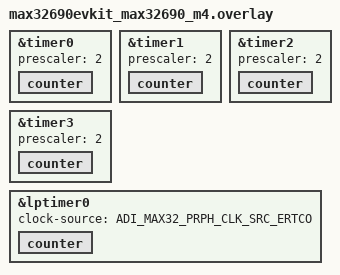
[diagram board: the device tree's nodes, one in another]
/*
 * Copyright (c) 2024 Analog Devices, Inc.
 *
 * SPDX-License-Identifier: Apache-2.0
 */

&timer0 {
	prescaler = <2>;
	status = "okay";

	counter {
		status = "okay";
	};
};

&timer1 {
	prescaler = <2>;
	status = "okay";

	counter {
		status = "okay";
	};
};

&timer2 {
	prescaler = <2>;
	status = "okay";

	counter {
		status = "okay";
	};
};

&timer3 {
	prescaler = <2>;
	status = "okay";

	counter {
		status = "okay";
	};
};

&lptimer0 {
	clock-source = <ADI_MAX32_PRPH_CLK_SRC_ERTCO>;
	status = "okay";

	counter {
		status = "okay";
	};
};
